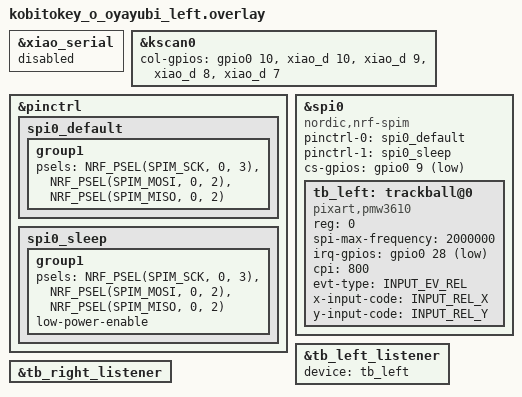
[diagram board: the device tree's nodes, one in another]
#include "kobitokey_o_oyayubi.dtsi"
#include <zephyr/dt-bindings/input/input-event-codes.h>

&xiao_serial { status = "disabled"; };

/* Left half: declare cols in REVERSE physical order so that kscan col 0 is
 * the outer pinky column (physical COL4 = P0.10) and kscan col 4 is the
 * inner index column (physical COL0 = P1.12). col-offset stays at 0 so
 * combined col 0 lands on the left pinky, matching standard QWERTY layout.
 *
 * Inputs (cols) get pull-down because the matrix is row2col scanning: a row
 * is driven HIGH and only the connected col reads HIGH through the diode. */
&kscan0 {
    col-gpios
        = <&gpio0 10 (GPIO_ACTIVE_HIGH | GPIO_PULL_DOWN)>  /* COL4 - P0.10 NFC2 (pinky) */
        , <&xiao_d 10 (GPIO_ACTIVE_HIGH | GPIO_PULL_DOWN)> /* COL3 - P1.15 (D10) */
        , <&xiao_d 9  (GPIO_ACTIVE_HIGH | GPIO_PULL_DOWN)> /* COL2 - P1.14 (D9) */
        , <&xiao_d 8  (GPIO_ACTIVE_HIGH | GPIO_PULL_DOWN)> /* COL1 - P1.13 (D8) */
        , <&xiao_d 7  (GPIO_ACTIVE_HIGH | GPIO_PULL_DOWN)> /* COL0 - P1.12 (D7) (inner) */
        ;
};

&pinctrl {
    spi0_default: spi0_default {
        group1 {
            psels = <NRF_PSEL(SPIM_SCK,  0, 3)>,
                    <NRF_PSEL(SPIM_MOSI, 0, 2)>,
                    <NRF_PSEL(SPIM_MISO, 0, 2)>;
        };
    };
    spi0_sleep: spi0_sleep {
        group1 {
            psels = <NRF_PSEL(SPIM_SCK,  0, 3)>,
                    <NRF_PSEL(SPIM_MOSI, 0, 2)>,
                    <NRF_PSEL(SPIM_MISO, 0, 2)>;
            low-power-enable;
        };
    };
};

&spi0 {
    status = "okay";
    compatible = "nordic,nrf-spim";
    pinctrl-0 = <&spi0_default>;
    pinctrl-1 = <&spi0_sleep>;
    pinctrl-names = "default", "sleep";
    cs-gpios = <&gpio0 9 GPIO_ACTIVE_LOW>;

    tb_left: trackball@0 {
        status = "okay";
        compatible = "pixart,pmw3610";
        reg = <0>;
        spi-max-frequency = <2000000>;
        irq-gpios = <&gpio0 28 (GPIO_ACTIVE_LOW | GPIO_PULL_UP)>;
        cpi = <800>;
        evt-type = <INPUT_EV_REL>;
        x-input-code = <INPUT_REL_X>;
        y-input-code = <INPUT_REL_Y>;
    };
};

&tb_left_listener {
    status = "okay";
    device = <&tb_left>;
};

&tb_right_listener {
    status = "okay";
};
